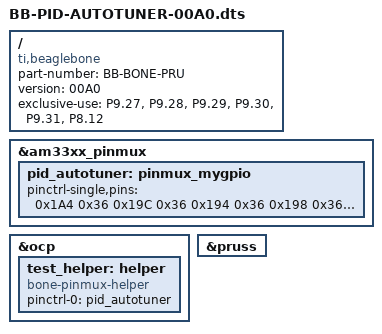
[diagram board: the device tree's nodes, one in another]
/*
* pru dts file BB-BONE-PRU-00A0.dts
*/
/dts-v1/;
/plugin/;

/ {
  compatible = "ti,beaglebone", "ti,beaglebone-black";

  /* identification */
  part-number = "BB-BONE-PRU";
  version = "00A0";

  exclusive-use =
    "P9.27",
    "P9.28",
    "P9.29",
    "P9.30",
    "P9.31",
    "P8.12";

  fragment@0 {
    target = <&am33xx_pinmux>;
    __overlay__ {
      pid_autotuner: pinmux_mygpio{
        pinctrl-single,pins = <
          0x1A4 0x36
          0x19C 0x36
          0x194 0x36
          0x198 0x36
          0x190 0x05
          0x30 0x06
          >;
      };
    };
  };

  fragment@1 {
    target = <&ocp>;
    __overlay__ {
      test_helper: helper {
        compatible = "bone-pinmux-helper";
        pinctrl-names = "default";
        pinctrl-0 = <&pid_autotuner>;
        status = "okay";
      };
    };
  };

  fragment@2{
  target = <&pruss>;
    __overlay__ {
      status = "okay";
    };
  };
};
